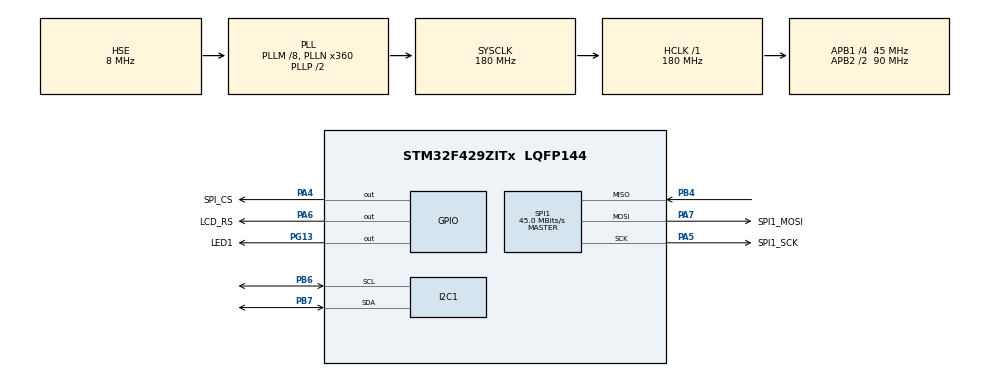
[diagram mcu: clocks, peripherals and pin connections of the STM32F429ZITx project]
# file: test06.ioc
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Mcu.Family=STM32F4
Mcu.Name=STM32F429ZITx
Mcu.Package=LQFP144
NVIC.PriorityGroup=NVIC_PRIORITYGROUP_4
PA13.Mode=Serial_Wire
PA13.Signal=SYS_JTMS-SWDIO
PA14.Mode=Serial_Wire
PA14.Signal=SYS_JTCK-SWCLK
PA4.GPIO_Label=SPI_CS
PA4.PinState=GPIO_PIN_SET
PA4.Signal=GPIO_Output
PA5.GPIO_Label=SPI1_SCK
PA5.Mode=Full_Duplex_Master
PA5.Signal=SPI1_SCK
PA6.GPIO_Label=LCD_RS
PA6.PinState=GPIO_PIN_RESET
PA6.Signal=GPIO_Output
PA7.GPIO_Label=SPI1_MOSI
PA7.Mode=Full_Duplex_Master
PA7.Signal=SPI1_MOSI
PB4.Mode=Full_Duplex_Master
PB4.Signal=SPI1_MISO
PB6.Mode=I2C
PB6.Signal=I2C1_SCL
PB7.Mode=I2C
PB7.Signal=I2C1_SDA
PG13.GPIO_Label=LED1
PG13.Signal=GPIO_Output
PH0/OSC_IN.Mode=HSE-External-Oscillator
PH0/OSC_IN.Signal=RCC_OSC_IN
PH1/OSC_OUT.Mode=HSE-External-Oscillator
PH1/OSC_OUT.Signal=RCC_OSC_OUT
ProjectManager.HeapSize=0x200
ProjectManager.StackSize=0x400
ProjectManager.TargetToolchain=MDK-ARM V5.32
RCC.48MHZClocksFreq_Value=90000000
RCC.AHBFreq_Value=180000000
RCC.APB1CLKDivider=RCC_HCLK_DIV4
RCC.APB1Freq_Value=45000000
RCC.APB1TimFreq_Value=90000000
RCC.APB2CLKDivider=RCC_HCLK_DIV2
RCC.APB2Freq_Value=90000000
RCC.APB2TimFreq_Value=180000000
RCC.CortexFreq_Value=180000000
RCC.HCLKFreq_Value=180000000
RCC.HSE_VALUE=8000000
RCC.HSI_VALUE=16000000
RCC.LSE_VALUE=32768
RCC.PLLM=8
RCC.PLLN=360
RCC.PLLSourceVirtual=RCC_PLLSOURCE_HSE
RCC.SYSCLKFreq_VALUE=180000000
RCC.SYSCLKSource=RCC_SYSCLKSOURCE_PLLCLK
RCC.VCOOutputFreq_Value=360000000
SPI1.CalculateBaudRate=45.0 MBits/s
SPI1.Direction=SPI_DIRECTION_2LINES
SPI1.Mode=SPI_MODE_MASTER
SPI1.VirtualType=VM_MASTER
board=custom

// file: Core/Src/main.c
/* USER CODE BEGIN Header */
/**
 ******************************************************************************
 * @file           : main.c
 * @brief          : Main program body
 ******************************************************************************
 * @attention
 *
 * Copyright (c) 2026 STMicroelectronics.
 * All rights reserved.
 *
 * This software is licensed under terms that can be found in the LICENSE file
 * in the root directory of this software component.
 * If no LICENSE file comes with this software, it is provided AS-IS.
 *
 ******************************************************************************
 */
/* USER CODE END Header */
#include "main.h"
#include "gpio.h"
#include "i2c.h"
#include "spi.h"

/* USER CODE BEGIN Includes */
#include "lcd_st7789v.h"
#include "icon_128x128.h"
#include "touch_CTP.h"
/* USER CODE END Includes */

void SystemClock_Config(void);

int main(void)
{

    /* MCU Configuration--------------------------------------------------------*/

    /* Reset of all peripherals, Initializes the Flash interface and the Systick. */
    HAL_Init();

    /* Configure the system clock */
    SystemClock_Config();

    /* Initialize all configured peripherals */
    MX_GPIO_Init();
    MX_I2C1_Init();
    MX_SPI1_Init();
    /* USER CODE BEGIN 2 */
    Lcd_Initialize();
		Touch_GPIO_Config();
    Lcd_ColorBox(0, 0, LCD_Width, LCD_Height, BLUE); //

    Lcd_ColorBox(0, 0, 240, 240, BLUE); //
    draw_Bat(130, 10, 3);               //

    LCD_PutString(60, 110, "钜润科技", RED, YELLOW, 1);
    LCD_PutString(60, 130, "www.hjrkj.com", RED, YELLOW, 1);

    //LCD_Fill_Pic(60,150,128, 64, (u8*)gImage_icon_128x128);
    /* USER CODE END 2 */

    /* Infinite loop */
    /* USER CODE BEGIN WHILE */
    while (1)
    {
			Touch_Test();
        /* USER CODE END WHILE */

    }
}

void SystemClock_Config(void)
{
    RCC_OscInitTypeDef RCC_OscInitStruct = {0};
    RCC_ClkInitTypeDef RCC_ClkInitStruct = {0};

    /** Configure the main internal regulator output voltage
     */
    __HAL_RCC_PWR_CLK_ENABLE();
    __HAL_PWR_VOLTAGESCALING_CONFIG(PWR_REGULATOR_VOLTAGE_SCALE1);

    /** Initializes the RCC Oscillators according to the specified parameters
     * in the RCC_OscInitTypeDef structure.
     */
    RCC_OscInitStruct.OscillatorType = RCC_OSCILLATORTYPE_HSE;
    RCC_OscInitStruct.HSEState = RCC_HSE_ON;
    RCC_OscInitStruct.PLL.PLLState = RCC_PLL_ON;
    RCC_OscInitStruct.PLL.PLLSource = RCC_PLLSOURCE_HSE;
    RCC_OscInitStruct.PLL.PLLM = 8;
    RCC_OscInitStruct.PLL.PLLN = 360;
    RCC_OscInitStruct.PLL.PLLP = RCC_PLLP_DIV2;
    RCC_OscInitStruct.PLL.PLLQ = 4;
    if (HAL_RCC_OscConfig(&RCC_OscInitStruct) != HAL_OK)
    {
        Error_Handler();
    }

    /** Activate the Over-Drive mode
     */
    if (HAL_PWREx_EnableOverDrive() != HAL_OK)
    {
        Error_Handler();
    }

    /** Initializes the CPU, AHB and APB buses clocks
     */
    RCC_ClkInitStruct.ClockType = RCC_CLOCKTYPE_HCLK | RCC_CLOCKTYPE_SYSCLK | RCC_CLOCKTYPE_PCLK1 | RCC_CLOCKTYPE_PCLK2;
    RCC_ClkInitStruct.SYSCLKSource = RCC_SYSCLKSOURCE_PLLCLK;
    RCC_ClkInitStruct.AHBCLKDivider = RCC_SYSCLK_DIV1;
    RCC_ClkInitStruct.APB1CLKDivider = RCC_HCLK_DIV4;
    RCC_ClkInitStruct.APB2CLKDivider = RCC_HCLK_DIV2;

    if (HAL_RCC_ClockConfig(&RCC_ClkInitStruct, FLASH_LATENCY_5) != HAL_OK)
    {
        Error_Handler();
    }
}

void Error_Handler(void)
{
    __disable_irq();
    while (1)
    {
    }
}
